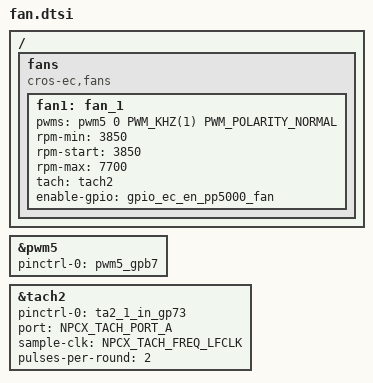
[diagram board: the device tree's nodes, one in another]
/* Copyright 2025 The ChromiumOS Authors
 * Use of this source code is governed by a BSD-style license that can be
 * found in the LICENSE file.
 */

/ {
	fans {
		compatible = "cros-ec,fans";

		fan1: fan_1 {
			pwms = <&pwm5 0 PWM_KHZ(1) PWM_POLARITY_NORMAL>;
			rpm-min = <3850>;
			rpm-start = <3850>;
			rpm-max = <7700>;
			tach = <&tach2>;
			enable-gpio = <&gpio_ec_en_pp5000_fan>;
		};
	};
};

&pwm5 {
	status = "okay";
	pinctrl-0 = <&pwm5_gpb7>;
	pinctrl-names = "default";
};

&tach2 {
	status = "okay";
	pinctrl-0 = <&ta2_1_in_gp73>;
	pinctrl-names = "default";
	port = <NPCX_TACH_PORT_A>;
	sample-clk = <NPCX_TACH_FREQ_LFCLK>;
	pulses-per-round = <2>;
};
